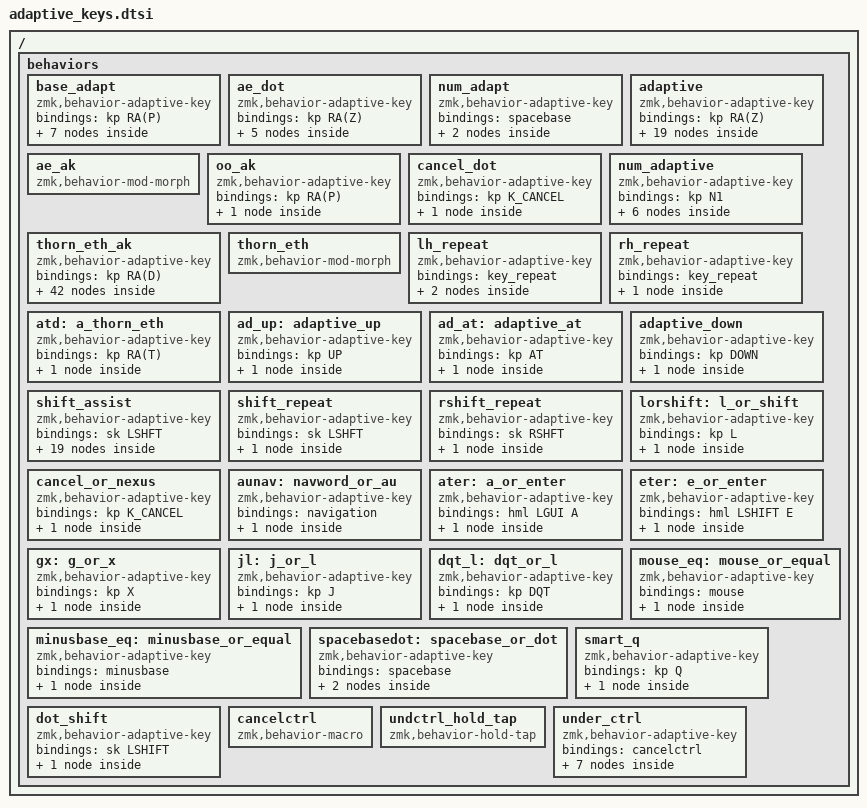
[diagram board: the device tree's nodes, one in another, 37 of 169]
/ {
	behaviors {

		base_adapt: base_adapt {
			compatible = "zmk,behavior-adaptive-key";
			#binding-cells = <0>;
			bindings = <&kp RA(P)>;
			ak_doti { trigger-keys = <DOT>; max-prior-idle-ms = <2000>; bindings = <&kp I>; };
			ak_idot { trigger-keys = <I>; max-prior-idle-ms = <2000>; bindings = <&kp DOT>; };
			ak_ydot { trigger-keys = <Y>; max-prior-idle-ms = <2000>; bindings = <&kp DOT>; };
			ak_7sp { trigger-keys = <N7>; max-prior-idle-ms = <2000>; bindings = <&kp SPACE>; };
			ak_8sp { trigger-keys = <N8>; max-prior-idle-ms = <2000>; bindings = <&kp SPACE>; };
			ak_9sp { trigger-keys = <N9>; max-prior-idle-ms = <2000>; bindings = <&kp SPACE>; };
			ak_0sp { trigger-keys = <N0>; max-prior-idle-ms = <2000>; bindings = <&kp SPACE>; };
		};

		ae_dot: ae_dot {
			compatible = "zmk,behavior-adaptive-key";
			#binding-cells = <0>;
			bindings = <&kp RA(Z)>;
			ak_doti { trigger-keys = <DOT>; max-prior-idle-ms = <2000>; bindings = <&kp I>; };
			ak_idot { trigger-keys = <I>; max-prior-idle-ms = <2000>; bindings = <&kp DOT>; };
			ak_ydot { trigger-keys = <Y>; max-prior-idle-ms = <2000>; bindings = <&kp DOT>; };
			ak_dot2 { trigger-keys = <DOT>; max-prior-idle-ms = <2000>; bindings = <&kp N2>; };
			ak_2dot { trigger-keys = <N2>; max-prior-idle-ms = <2000>; bindings = <&kp DOT>; };
		};

		num_adapt: num_adapt {
			compatible = "zmk,behavior-adaptive-key";
			#binding-cells = <0>;
			bindings = <&spacebase>;
			ak_dot2 { trigger-keys = <DOT>; max-prior-idle-ms = <2000>; bindings = <&kp N2>; };
			ak_2dot { trigger-keys = <N2>; max-prior-idle-ms = <2000>; bindings = <&kp DOT>; };
		};

		adaptive: adaptive {
			compatible = "zmk,behavior-adaptive-key";
			#binding-cells = <0>;
			bindings = <&kp RA(Z)>;

			/* ak_idot { trigger-keys = <I>; max-prior-idle-ms = <1000>; bindings = <&kp DOT>; }; */
			ak_doti { trigger-keys = <DOT>; max-prior-idle-ms = <1000>; bindings = <&kp I>; };
			ak_iy { trigger-keys = <I>; max-prior-idle-ms = <2000>; bindings = <&kp Y>; };
			ak_yi { trigger-keys = <Y>; max-prior-idle-ms = <2000>; bindings = <&kp I>; };
			ak_eo { trigger-keys = <E>; max-prior-idle-ms = <2000>; bindings = <&kp O>; };
			ak_oe { trigger-keys = <O>; max-prior-idle-ms = <2000>; bindings = <&kp E>; };
			ak_au { trigger-keys = <A>; max-prior-idle-ms = <2000>; bindings = <&kp U>; };
			ak_ua { trigger-keys = <U>; max-prior-idle-ms = <2000>; bindings = <&kp A>; };
			/* ak_eu { trigger-keys = <E>; max-prior-idle-ms = <2000>; bindings = <&kp U>; }; */
			/* ak_ue { trigger-keys = <U>; max-prior-idle-ms = <2000>; bindings = <&kp E>; }; */
			/* ak_ao { trigger-keys = <A>; max-prior-idle-ms = <2000>; bindings = <&kp O>; }; */
			/* ak_oa { trigger-keys = <O>; max-prior-idle-ms = <2000>; bindings = <&kp A>; }; */

			/* ak_ww { trigger-keys = <W>; max-prior-idle-ms = <2000>; bindings = <&kp W>; }; */
			ak_ls { trigger-keys = <L>; max-prior-idle-ms = <2000>; bindings = <&kp S>; };

			ak_cspace { trigger-keys = <C>; max-prior-idle-ms = <2000>; bindings = <&kp SPACE>; };
			/* ak_underspace { trigger-keys = <UNDER>; max-prior-idle-ms = <600>; bindings = <&kp SPACE>; }; */
			ak_0space { trigger-keys = <N0>; max-prior-idle-ms = <2000>; bindings = <&kp SPACE>; };
			ak_1space { trigger-keys = <N1>; max-prior-idle-ms = <2000>; bindings = <&kp SPACE>; };
			ak_2space { trigger-keys = <N2>; max-prior-idle-ms = <2000>; bindings = <&kp SPACE>; };
			ak_3space { trigger-keys = <N3>; max-prior-idle-ms = <2000>; bindings = <&kp SPACE>; };
			ak_4space { trigger-keys = <N4>; max-prior-idle-ms = <2000>; bindings = <&kp SPACE>; };
			ak_5space { trigger-keys = <N5>; max-prior-idle-ms = <2000>; bindings = <&kp SPACE>; };
			ak_6space { trigger-keys = <N6>; max-prior-idle-ms = <2000>; bindings = <&kp SPACE>; };
			ak_7space { trigger-keys = <N7>; max-prior-idle-ms = <2000>; bindings = <&kp SPACE>; };
			ak_8space { trigger-keys = <N8>; max-prior-idle-ms = <2000>; bindings = <&kp SPACE>; };
			ak_9space { trigger-keys = <N9>; max-prior-idle-ms = <2000>; bindings = <&kp SPACE>; };
				
			/* ak_nl { trigger-keys = <N>; max-prior-idle-ms = <2000>; bindings = <&kp L>; }; */
			/* ak_dv { trigger-keys = <D>; max-prior-idle-ms = <2000>; bindings = <&kp V>; }; */
			/* ak_gd { trigger-keys = <G>; max-prior-idle-ms = <1000>; bindings = <&kp D>; }; */
			/* ak_bn { trigger-keys = <B>; max-prior-idle-ms = <2000>; bindings = <&kp N>; }; */
			/* ak_td { trigger-keys = <T>; max-prior-idle-ms = <2000>; bindings = <&kp D>; }; */
			/* ak_ratj { trigger-keys = <RA(T)>; max-prior-idle-ms = <2000>; bindings = <&kp J>; }; Virkar því miður ekki, registerar bara sem T RANGT þarft bara nota strict-modifiers */ 

			/* ak_kr { trigger-keys = <K>; max-prior-idle-ms = <2000>; bindings = <&kp R>; }; */
			/* ak_sr { trigger-keys = <S>; max-prior-idle-ms = <2000>; bindings = <&kp R>; }; */
     
			/* ak_spacec { trigger-keys = <SPACE>; max-prior-idle-ms = <2000>; bindings = <&kp C>; }; */
			/* ak_vt { trigger-keys = <V>; max-prior-idle-ms = <2000>; bindings = <&kp T>; }; fyrir vt (velja til) í vim */ 
		};

		ae_ak: ae_ak {
			compatible = "zmk,behavior-mod-morph";
			#binding-cells = <0>;
			bindings = <&adaptive>, <&kp W>;
			mods = <(MOD_LCTL|MOD_RCTL|MOD_LALT|MOD_RALT|MOD_LGUI|MOD_RGUI)>;
			keep-mods = <(MOD_LCTL|MOD_RCTL|MOD_LALT|MOD_RALT|MOD_LGUI|MOD_RGUI)>;
		};

		oo_ak: oo_ak {
			compatible = "zmk,behavior-adaptive-key";
			#binding-cells = <0>;
			bindings = <&kp RA(P)>;

			ak_ydot { trigger-keys = <Y>; max-prior-idle-ms = <2000>; bindings = <&kp DOT>; };
		};

		cancel_dot: cancel_dot {
			compatible = "zmk,behavior-adaptive-key";
			#binding-cells = <0>;
			bindings = <&kp K_CANCEL>;

			ak_ydot { trigger-keys = <Y>; max-prior-idle-ms = <2000>; bindings = <&kp DOT>; };
		};

		num_adaptive: num_adaptive {
			compatible = "zmk,behavior-adaptive-key";
			#binding-cells = <0>;
			bindings = <&kp N1>;

			ak_31 { trigger-keys = <N3>; max-prior-idle-ms = <2000>; bindings = <&kp N1>; };
			ak_15 { trigger-keys = <N1>; max-prior-idle-ms = <2000>; bindings = <&kp N5>; };
			ak_55 { trigger-keys = <N5>; max-prior-idle-ms = <2000>; bindings = <&kp N5>; };

			ak_80 { trigger-keys = <N8>; max-prior-idle-ms = <2000>; bindings = <&kp N0>; };
			ak_06 { trigger-keys = <N0>; max-prior-idle-ms = <2000>; bindings = <&kp N6>; };
			ak_66 { trigger-keys = <N6>; max-prior-idle-ms = <2000>; bindings = <&kp N6>; };
		};

		thorn_eth_ak: thorn_eth_ak {
			compatible = "zmk,behavior-adaptive-key";
			#binding-cells = <0>;
			bindings = <&kp RA(D)>;

			ak_thorn_eth1 { trigger-keys = <SPACE>; bindings = <&kp RA(T)>; };
			ak_thorn_eth2 { trigger-keys = <LSHIFT>; bindings = <&kp RA(T)>; };
			ak_thorn_eth3 { trigger-keys = <RSHIFT>; bindings = <&kp RA(T)>; };
			ak_thorn_eth4 { trigger-keys = <LPAR>; bindings = <&kp RA(T)>; };
			ak_thorn_eth5 { trigger-keys = <LBRC>; bindings = <&kp RA(T)>; };
			ak_thorn_eth6 { trigger-keys = <LBKT>; bindings = <&kp RA(T)>; };
			ak_thorn_eth7 { trigger-keys = <LT>; bindings = <&kp RA(T)>; };
			ak_thorn_eth8 { trigger-keys = <DQT>; bindings = <&kp RA(T)>; };
			ak_thorn_eth9 { trigger-keys = <SQT>; bindings = <&kp RA(T)>; };
			ak_thorn_eth10 { trigger-keys = <ENTER>; bindings = <&kp RA(T)>; };
			/* ak_thorn_eth11 { trigger-keys = <K_CANCEL>; bindings = <&kp RA(T)>; }; */
			ak_thorn_eth12 { trigger-keys = <MINUS>; bindings = <&kp RA(T)>; };
			ak_thorn_eth13 { trigger-keys = <UNDERSCORE>; bindings = <&kp RA(T)>; };

			ak_bl { trigger-keys = <B>; max-prior-idle-ms = <2000>; bindings = <&kp L>; }; 
			ak_bn { trigger-keys = <B>; max-prior-idle-ms = <2000>; bindings = <&kp N>; };
			ak_lb { trigger-keys = <L>; max-prior-idle-ms = <2000>; bindings = <&kp B>; };
			ak_tv { trigger-keys = <T>; max-prior-idle-ms = <2000>; bindings = <&kp V>; strict-modifiers; };
			ak_lstv { trigger-keys = <LS(T)>; max-prior-idle-ms = <2000>; bindings = <&kp V>; strict-modifiers; };
			ak_rstv { trigger-keys = <RS(T)>; max-prior-idle-ms = <2000>; bindings = <&kp V>; strict-modifiers; };
			ak_dg { trigger-keys = <D>; max-prior-idle-ms = <2000>; bindings = <&kp G>; strict-modifiers; };
			/* ak_kl { trigger-keys = <K>; max-prior-idle-ms = <2000>; bindings = <&kp L>; }; */
			ak_zb { trigger-keys = <Z>; max-prior-idle-ms = <2000>; bindings = <&kp B>; strict-modifiers; }; /* strict fyrir æð */

			ak_nl { trigger-keys = <N>; max-prior-idle-ms = <2000>; bindings = <&kp L>; };
			/* ak_nk { trigger-keys = <N>; max-prior-idle-ms = <2000>; bindings = <&kp K>; }; */

      /* Skv BÍN koma eftirfarandi pör aldrei fyrir: */
      /* LÐ, BÐ, PÐ, TÐ, KÐ, SÐ, DÐ, NÐ, HÐ */
      /* Þar með ætti að vera í lagi að hafa þau hér,  */
      /* en er með nl, dg, gd uppi samt, vil ekki tvítaka þau */
      /* (og er með td og bn uppi líka svo t og b eru báðu megin) */

			/* ak_ck { trigger-keys = <C>; max-prior-idle-ms = <2000>; bindings = <&kp K>; }; */
			/* ak_sk { trigger-keys = <S>; max-prior-idle-ms = <2000>; bindings = <&kp K>; }; */
			ak_sf { trigger-keys = <S>; max-prior-idle-ms = <2000>; bindings = <&kp F>; };
			ak_kr { trigger-keys = <K>; max-prior-idle-ms = <2000>; bindings = <&kp R>; };
			ak_pj { trigger-keys = <P>; max-prior-idle-ms = <2000>; bindings = <&kp J>; strict-modifiers; }; /* strict fyrir öð */
			ak_lspj { trigger-keys = <LS(P)>; max-prior-idle-ms = <2000>; bindings = <&kp J>; strict-modifiers; };
			ak_rspj { trigger-keys = <RS(P)>; max-prior-idle-ms = <2000>; bindings = <&kp J>; strict-modifiers; };
			ak_jp { trigger-keys = <J>; max-prior-idle-ms = <2000>; bindings = <&kp P>; };

			/* ak_hj { trigger-keys = <H>; max-prior-idle-ms = <2000>; bindings = <&kp J>; }; */
			/* ak_sj { trigger-keys = <S>; max-prior-idle-ms = <2000>; bindings = <&kp J>; }; */
			/* ak_kn { trigger-keys = <K>; max-prior-idle-ms = <2000>; bindings = <&kp N>; }; */


			ak_xp { trigger-keys = <X>; max-prior-idle-ms = <2000>; bindings = <&kp P>; };

			ak_tabrep { trigger-keys = <TAB>; max-prior-idle-ms = <2000>; bindings = <&kp TAB>; };

      
      /* man ekki af hveru ég gerði þetta strict-modifiers en uuhh treystum mér I guess */
			ak_cspace { trigger-keys = <C>; max-prior-idle-ms = <2000>; strict-modifiers; bindings = <&kp SPACE>; };
			ak_clcapspace { trigger-keys = <LS(C)>; max-prior-idle-ms = <2000>; strict-modifiers; bindings = <&kp SPACE>; };
			ak_crcapspace { trigger-keys = <RS(C)>; max-prior-idle-ms = <2000>; strict-modifiers; bindings = <&kp SPACE>; };

			ak_n0space { trigger-keys = <N0>; max-prior-idle-ms = <2000>; bindings = <&kp SPACE>; };
			ak_n1space { trigger-keys = <N1>; max-prior-idle-ms = <2000>; bindings = <&kp SPACE>; };
			ak_n2space { trigger-keys = <N2>; max-prior-idle-ms = <2000>; bindings = <&kp SPACE>; };
			ak_n3space { trigger-keys = <N3>; max-prior-idle-ms = <2000>; bindings = <&kp SPACE>; };
			ak_n4space { trigger-keys = <N4>; max-prior-idle-ms = <2000>; bindings = <&kp SPACE>; };
			ak_n5space { trigger-keys = <N5>; max-prior-idle-ms = <2000>; bindings = <&kp SPACE>; };
			ak_n6space { trigger-keys = <N6>; max-prior-idle-ms = <2000>; bindings = <&kp SPACE>; };
			ak_n7space { trigger-keys = <N7>; max-prior-idle-ms = <2000>; bindings = <&kp SPACE>; };
			ak_n8space { trigger-keys = <N8>; max-prior-idle-ms = <2000>; bindings = <&kp SPACE>; };
			ak_n9space { trigger-keys = <N9>; max-prior-idle-ms = <2000>; bindings = <&kp SPACE>; };
		};

		thorn_eth: thorn_eth {
			compatible = "zmk,behavior-mod-morph";
			#binding-cells = <0>;
			bindings = <&thorn_eth_ak>, <&kp P>;
			mods = <(MOD_LCTL|MOD_RCTL|MOD_LALT|MOD_RALT|MOD_LGUI|MOD_RGUI)>;
			keep-mods = <(MOD_LCTL|MOD_RCTL|MOD_LALT|MOD_RALT|MOD_LGUI|MOD_RGUI)>;
		};

		lh_repeat: lh_repeat {
			compatible = "zmk,behavior-adaptive-key";
			#binding-cells = <0>;
			bindings = <&key_repeat>;
			ak_gd { trigger-keys = <G>; max-prior-idle-ms = <2000>; bindings = <&kp D>; };
			ak_bl { trigger-keys = <B>; max-prior-idle-ms = <2000>; bindings = <&kp L>; };
		};


		rh_repeat: rh_repeat {
			compatible = "zmk,behavior-adaptive-key";
			#binding-cells = <0>;
			bindings = <&key_repeat>;
			/* ak_lj { trigger-keys = <L>; max-prior-idle-ms = <2000>; bindings = <&kp J>; }; */
			ak_eq { trigger-keys = <E>; max-prior-idle-ms = <2000>; bindings = <&kp Q>; };
		};

		atd: a_thorn_eth {
			compatible = "zmk,behavior-adaptive-key";
			#binding-cells = <0>;
			bindings = <&kp RA(T)>;

			ak_razrad { trigger-keys = <RA(Z)>; max-prior-idle-ms = <2000>; bindings = <&kp RA(D)>; };
		};

		ad_up: adaptive_up {
			compatible = "zmk,behavior-adaptive-key";
			#binding-cells = <0>;
			bindings = <&kp UP>;

			/* ak_gl { trigger-keys = <G>; max-prior-idle-ms = <1000>; bindings = <&kp D>; }; */
			ak_gl { trigger-keys = <G>; max-prior-idle-ms = <1000>; bindings = <&kp L>; };
		};

		ad_at: adaptive_at {
			compatible = "zmk,behavior-adaptive-key";
			#binding-cells = <0>;
			bindings = <&kp AT>;

			/* ak_gl { trigger-keys = <G>; max-prior-idle-ms = <1000>; bindings = <&kp D>; }; */
			ak_gl2 { trigger-keys = <G>; max-prior-idle-ms = <1000>; bindings = <&kp L>; };
		};

		adaptive_down: adaptive_down {
			compatible = "zmk,behavior-adaptive-key";
			#binding-cells = <0>;
			bindings = <&kp DOWN>;

			ak_gv { trigger-keys = <G>; max-prior-idle-ms = <1000>; bindings = <&kp V>; };
		};

		shift_assist: shift_assist {
			compatible = "zmk,behavior-adaptive-key";
			#binding-cells = <0>;
			bindings = <&sk LSHFT>;

			ak_iy { trigger-keys = <I>; max-prior-idle-ms = <350>; strict-modifiers; bindings = <&kp Y>; };
			ak_yi { trigger-keys = <Y>; max-prior-idle-ms = <350>; strict-modifiers; bindings = <&kp I>; };
			ak_eo { trigger-keys = <E>; max-prior-idle-ms = <350>; strict-modifiers; bindings = <&kp O>; };
			ak_oe { trigger-keys = <O>; max-prior-idle-ms = <350>; strict-modifiers; bindings = <&kp E>; };
			ak_au { trigger-keys = <A>; max-prior-idle-ms = <350>; strict-modifiers; bindings = <&kp U>; };
			ak_ua { trigger-keys = <U>; max-prior-idle-ms = <350>; strict-modifiers; bindings = <&kp A>; };
			ak_zz   { trigger-keys = <Z>; max-prior-idle-ms = <350>; strict-modifiers; bindings = <&kp Z>; };
			ak_vae  { trigger-keys = <V>; max-prior-idle-ms = <350>; strict-modifiers; bindings = <&kp RA(Z)>; };
				
			ak_fr { trigger-keys = <F>; max-prior-idle-ms = <350>; strict-modifiers; bindings = <&kp R>; };
			ak_wr { trigger-keys = <W>; max-prior-idle-ms = <350>; strict-modifiers; bindings = <&kp R>; };
			ak_pr { trigger-keys = <P>; max-prior-idle-ms = <350>; strict-modifiers; bindings = <&kp R>; };
			ak_nl { trigger-keys = <N>; max-prior-idle-ms = <350>; strict-modifiers; bindings = <&kp L>; };
			ak_dg { trigger-keys = <D>; max-prior-idle-ms = <350>; strict-modifiers; bindings = <&kp G>; };
			/* ak_gl { trigger-keys = <G>; max-prior-idle-ms = <350>; strict-modifiers; bindings = <&kp L>; }; */
			ak_lg { trigger-keys = <L>; max-prior-idle-ms = <350>; strict-modifiers; bindings = <&kp G>; };
			ak_td { trigger-keys = <T>; max-prior-idle-ms = <350>; strict-modifiers; bindings = <&kp D>; };

			ak_rs { trigger-keys = <R>; max-prior-idle-ms = <350>; strict-modifiers; bindings = <&kp S>; };
			ak_sr { trigger-keys = <S>; max-prior-idle-ms = <350>; strict-modifiers; bindings = <&kp R>; };
     
			ak_spacec { trigger-keys = <SPACE>; max-prior-idle-ms = <350>; strict-modifiers; bindings = <&kp C>; };

			space {
				trigger-keys = <C B N5>;
				bindings = <&kp SPACE>;
				max-prior-idle-ms = <350>;
				strict-modifiers;
			};
		};

		shift_repeat: shift_repeat {
			compatible = "zmk,behavior-adaptive-key";
			#binding-cells = <0>;
			bindings = <&sk LSHFT>;
			repeat {
				trigger-keys = <G B>; /* Aaaahg held B virki ekki í vim */
				bindings = <&key_repeat>;
				max-prior-idle-ms = <600>;
				strict-modifiers;
			};

			/* ak_ydot { trigger-keys = <Y>; max-prior-idle-ms = <1000>; bindings = <&kp DOT>; }; */
		};


		rshift_repeat: rshift_repeat {
			compatible = "zmk,behavior-adaptive-key";
			#binding-cells = <0>;
			bindings = <&sk RSHFT>;
			repeat {
				trigger-keys = <P L X Z LS(Z) K C>;
				bindings = <&key_repeat>;
				max-prior-idle-ms = <600>;
				strict-modifiers;
			};

			/* ak_eq { trigger-keys = <E>; max-prior-idle-ms = <600>; bindings = <&kp Q>; }; */
		};

		lorshift: l_or_shift {
			compatible = "zmk,behavior-adaptive-key";
			#binding-cells = <0>;
			bindings = <&kp L>;
			ak_knexus { trigger-keys = <L>; max-prior-idle-ms = <600>; bindings = <&sk LSHIFT>; };
		};

		cancel_or_nexus: cancel_or_nexus {
			compatible = "zmk,behavior-adaptive-key";
			#binding-cells = <0>;
			bindings = <&kp K_CANCEL>;
			ak_knexus { trigger-keys = <K>; max-prior-idle-ms = <800>; bindings = <&sll NEXUS>; };
		};

		aunav: navword_or_au {
			compatible = "zmk,behavior-adaptive-key";
			#binding-cells = <0>;
			bindings = <&navigation>;
			ak_knexus { trigger-keys = <A>; max-prior-idle-ms = <600>; bindings = <&kp U>; };
		};

		ater: a_or_enter {
			compatible = "zmk,behavior-adaptive-key";
			#binding-cells = <0>;
			bindings = <&hml LGUI A>;
			ak_knexus { trigger-keys = <DOT>; max-prior-idle-ms = <600>; bindings = <&kp ENTER>; };
		};

		eter: e_or_enter {
			compatible = "zmk,behavior-adaptive-key";
			#binding-cells = <0>;
			bindings = <&hml LSHIFT E>;
			ak_knexus { trigger-keys = <DOT>; max-prior-idle-ms = <600>; bindings = <&kp ENTER>; };
		};

		gx: g_or_x {
			compatible = "zmk,behavior-adaptive-key";
			#binding-cells = <0>;
			bindings = <&kp X>;
			ak_knexus { trigger-keys = <G>; max-prior-idle-ms = <600>; bindings = <&kp L>; };
		};

		jl: j_or_l {
			compatible = "zmk,behavior-adaptive-key";
			#binding-cells = <0>;
			bindings = <&kp J>;
			ak_knexus { trigger-keys = <G>; max-prior-idle-ms = <600>; bindings = <&kp L>; };
		};

		dqt_l: dqt_or_l {
			compatible = "zmk,behavior-adaptive-key";
			#binding-cells = <0>;
			bindings = <&kp DQT>;
			ak_knexus { trigger-keys = <G>; max-prior-idle-ms = <1500>; bindings = <&kp L>; };
		};

		mouse_eq: mouse_or_equal {
			compatible = "zmk,behavior-adaptive-key";
			#binding-cells = <0>;
			bindings = <&mouse>;
			ak_knexus { trigger-keys = <GT>; max-prior-idle-ms = <600>; bindings = <&kp EQUAL>; };
		};

		minusbase_eq: minusbase_or_equal {
			compatible = "zmk,behavior-adaptive-key";
			#binding-cells = <0>;
			bindings = <&minusbase>;
			ak_knexus { trigger-keys = <GT>; max-prior-idle-ms = <600>; bindings = <&kp EQUAL>; };
		};



    spacebasedot: spacebase_or_dot {
			compatible = "zmk,behavior-adaptive-key";
			#binding-cells = <0>;
			bindings = <&spacebase>;
			ak_n2dot { trigger-keys = <N2>; max-prior-idle-ms = <1000>; bindings = <&kp DOT>; };
			ak_dotn2 { trigger-keys = <DOT>; max-prior-idle-ms = <1000>; bindings = <&kp N2>; };
		};

    /* fyrir ZQ ofc */
    smart_q: smart_q {
			compatible = "zmk,behavior-adaptive-key";
			#binding-cells = <0>;
			bindings = <&kp Q>;
			ak_idot { trigger-keys = <LS(Z)>; max-prior-idle-ms = <800>; bindings = <&kp LS(Q)>; strict-modifiers; };
		};

		dot_shift: dot_shift {
			compatible = "zmk,behavior-adaptive-key";
			#binding-cells = <0>;
			bindings = <&sk LSHIFT>;
			repeat {
				trigger-keys = <A B C D E F G H I J K L M N O P Q R S T U V W X Y Z>;
				bindings = <&kp DOT>;
				max-prior-idle-ms = <600>;
				strict-modifiers;
			};
    };


		cancelctrl: cancelctrl {
			compatible = "zmk,behavior-macro";
			#binding-cells = <0>;
			wait-ms = <0>;
			tap-ms = <0>;
			bindings = <&kp K_CANCEL>, <&sk LCTRL>;
		};


		undctrl_hold_tap: undctrl_hold_tap {
		  compatible = "zmk,behavior-hold-tap";
		  #binding-cells = <2>;
		  flavor = "balanced";
		  tapping-term-ms = <200>;
		  bindings = <&kp>, <&under_ctrl>;
		};

    #define undctrl undctrl_hold_tap LCTRL 0

		under_ctrl: under_ctrl {
			compatible = "zmk,behavior-adaptive-key";
			#binding-cells = <0>;
			bindings = <&cancelctrl>;
			und {
				trigger-keys = <A B C D E F G H I J K L M N O P Q R S T U V W X Y Z>;
				bindings = <&kp UNDER>;
				max-prior-idle-ms = <1000>;
				strict-modifiers;
			};
      
			und_ls {
				trigger-keys = <LS(A) LS(B) LS(C) LS(D) LS(E) LS(F) LS(G) LS(H) LS(I) LS(J) LS(K) LS(L) LS(M) LS(N) LS(O) LS(P) LS(Q) LS(R) LS(S) LS(T) LS(U) LS(V) LS(W) LS(X) LS(Y) LS(Z)>;
				bindings = <&kp UNDER>;
				max-prior-idle-ms = <1000>;
				strict-modifiers;
			};

			und_rs {
				trigger-keys = <RS(A) RS(B) RS(C) RS(D) RS(E) RS(F) RS(G) RS(H) RS(I) RS(J) RS(K) RS(L) RS(M) RS(N) RS(O) RS(P) RS(Q) RS(R) RS(S) RS(T) RS(U) RS(V) RS(W) RS(X) RS(Y) RS(Z)>;
				bindings = <&kp UNDER>;
				max-prior-idle-ms = <1000>;
				strict-modifiers;
			};

			und_ra {
				trigger-keys = <RA(A) RA(D) RA(E) RA(I) RA(O) RA(P) RA(T) RA(U) RA(Y) RA(Z)>;
				bindings = <&kp UNDER>;
				max-prior-idle-ms = <1000>;
				strict-modifiers;
			};
			und_lsra {
				trigger-keys = <LS(RA(A)) LS(RA(D)) LS(RA(E)) LS(RA(I)) LS(RA(O)) LS(RA(P)) LS(RA(T)) LS(RA(U)) LS(RA(Y)) LS(RA(Z))>;
				bindings = <&kp UNDER>;
				max-prior-idle-ms = <1000>;
				strict-modifiers;
			};
			und_rsra {
				trigger-keys = <RS(RA(A)) RS(RA(D)) RS(RA(E)) RS(RA(I)) RS(RA(O)) RS(RA(P)) RS(RA(T)) RS(RA(U)) RS(RA(Y)) RS(RA(Z))>;
				bindings = <&kp UNDER>;
				max-prior-idle-ms = <1000>;
				strict-modifiers;
			};


			und_num {
				trigger-keys = <N0 N1 N2 N3 N4 N5 N6 N7 N8 N9>;
				bindings = <&kp UNDER>;
				max-prior-idle-ms = <1000>;
				strict-modifiers;
			};
		};

  };
};
